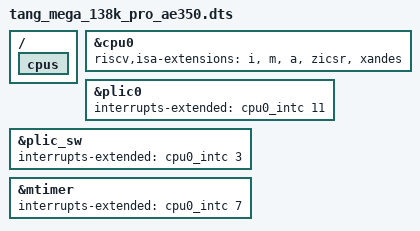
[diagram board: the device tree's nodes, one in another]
/*
 * Copyright The Zephyr Project Contributors
 *
 * SPDX-License-Identifier: Apache-2.0
 */

#include <riscv/andes/andes_v5_ae350.dtsi>

/ {
	cpus {
		/delete-node/ cpu@1;
		/delete-node/ cpu@2;
		/delete-node/ cpu@3;
		/delete-node/ cpu@4;
		/delete-node/ cpu@5;
		/delete-node/ cpu@6;
		/delete-node/ cpu@7;
	};
};

&cpu0 {
	riscv,isa-extensions = "i", "m", "a", "zicsr", "xandes";
};

&plic0 {
	interrupts-extended = <&cpu0_intc 11>;
};

&plic_sw {
	interrupts-extended = <&cpu0_intc 3>;
};

&mtimer {
	interrupts-extended = <&cpu0_intc 7>;
};
